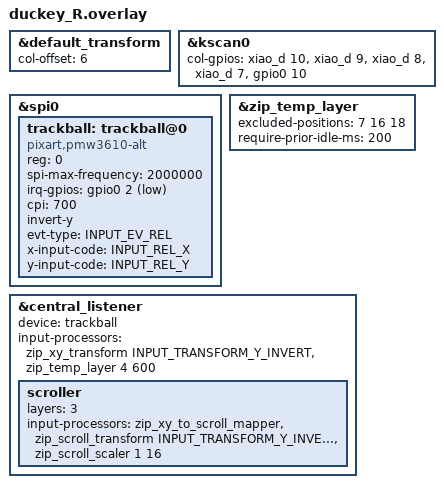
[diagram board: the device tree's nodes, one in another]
#include "duckey.dtsi"
#include <input/processors.dtsi>
#include <zephyr/dt-bindings/input/input-event-codes.h>

&default_transform {
    col-offset = <6>;
};

&kscan0 {
    col-gpios
        = <&xiao_d 10 GPIO_ACTIVE_HIGH>
        , <&xiao_d 9 GPIO_ACTIVE_HIGH>
        , <&xiao_d 8 GPIO_ACTIVE_HIGH>
        , <&xiao_d 7 GPIO_ACTIVE_HIGH>
        , <&gpio0 10 GPIO_ACTIVE_HIGH>
        ;
};

&spi0 {
    status = "okay";

    trackball: trackball@0 {
        status = "okay";
        compatible = "pixart,pmw3610-alt";
        reg = <0>;
        spi-max-frequency = <2000000>;
        irq-gpios = <&gpio0 2 (GPIO_ACTIVE_LOW | GPIO_PULL_UP)>;
        cpi = <700>;
        invert-y;
        evt-type = <INPUT_EV_REL>;
        x-input-code = <INPUT_REL_X>;
        y-input-code = <INPUT_REL_Y>;
    };
};

// zip_temp_layerの設定
&zip_temp_layer {
    excluded-positions = <
        7 16 18
    >;
    require-prior-idle-ms = <200>;
};

// セントラルのリスナーを有効化し、deviceを紐付け
&central_listener {
    status = "okay";
    device = <&trackball>;
    input-processors =
        <&zip_xy_transform INPUT_TRANSFORM_Y_INVERT>,
        <&zip_temp_layer 4 600>;

    scroller {
        layers = <3>;
        input-processors =
            <&zip_xy_to_scroll_mapper>,
            <&zip_scroll_transform INPUT_TRANSFORM_Y_INVERT>,
            <&zip_scroll_scaler 1 16>;
    };
};
